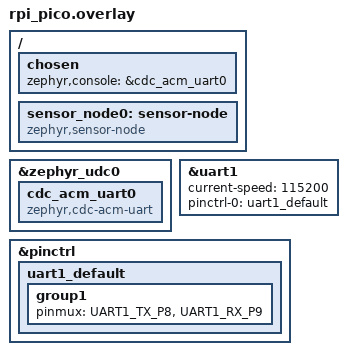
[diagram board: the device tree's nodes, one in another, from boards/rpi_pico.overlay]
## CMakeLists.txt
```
# SPDX-License-Identifier: Apache-2.0

cmake_minimum_required(VERSION 3.20.0)

find_package(Zephyr REQUIRED HINTS $ENV{ZEPHYR_BASE})
project(base_node)

target_sources(app PRIVATE
    src/main.c
    src/uart_handler.c
)
```

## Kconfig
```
# Base Node application Kconfig file

source "Kconfig.zephyr"

# Custom Kconfig options for sensor node
config SENSOR_NODE_UART_DEVICE
	string "UART Device for sensor node communication"
	default "UART_0"
	help
	  UART device to use for communication with the sensor node.

config CONSOLE_UART_DEVICE
	string "UART Device for console output"
	default "UART_1"
	help
	  UART device to use for console output.

config INTERRUPT_PIN
	int "Interrupt pin number"
	default 2
	help
	  GPIO pin number used for interrupt signal from sensor node.
```

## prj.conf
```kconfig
# USB CDC ACM Configuration
CONFIG_USB_DEVICE_STACK=y
CONFIG_USB_CDC_ACM=y

# UART Configuration
CONFIG_SERIAL=y
CONFIG_UART_INTERRUPT_DRIVEN=y
CONFIG_UART_LINE_CTRL=y
CONFIG_UART_CONSOLE=y

# Console and Logging
CONFIG_CONSOLE=y
CONFIG_STDOUT_CONSOLE=y
CONFIG_PRINTK=y
CONFIG_LOG=y
CONFIG_LOG_MODE_IMMEDIATE=y
CONFIG_LOG_DEFAULT_LEVEL=3

# GPIO Configuration
CONFIG_GPIO=y

# Memory Settings
CONFIG_HEAP_MEM_POOL_SIZE=4096
CONFIG_MAIN_STACK_SIZE=1024
CONFIG_ISR_STACK_SIZE=1024

# Build Output
CONFIG_BUILD_OUTPUT_UF2=y
```

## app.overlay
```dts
/ {
    chosen {
        zephyr,console = &cdc_acm_uart0;
    };

    /* Define our sensor node device */
    sensor_node0: sensor-node {
        compatible = "sensor-node";
        status = "okay";
    };
};

&uart0 {
    current-speed = <115200>;
    status = "okay";
};

&zephyr_udc0 {
    cdc_acm_uart0: cdc_acm_uart0 {
        compatible = "zephyr,cdc-acm-uart";
    };
};
```

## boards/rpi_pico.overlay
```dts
/*
 * Base Node Device Tree Overlay
 * Configures UART, I2C, and GPIO for the base node
 */

/ {
    chosen {
        zephyr,console = &cdc_acm_uart0;
    };

    sensor_node0: sensor-node {
        compatible = "zephyr,sensor-node";
        status = "okay";
    };
};

&zephyr_udc0 {
    cdc_acm_uart0: cdc_acm_uart0 {
        compatible = "zephyr,cdc-acm-uart";
    };
};

&uart1 {
    status = "okay";
    current-speed = <115200>;
    pinctrl-0 = <&uart1_default>;
    pinctrl-names = "default";
};

&pinctrl {
    uart1_default: uart1_default {
        group1 {
            pinmux = <UART1_TX_P8>, <UART1_RX_P9>;
        };
    };
};
```

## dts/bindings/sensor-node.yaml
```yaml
# Copyright (c) 2023
# SPDX-License-Identifier: Apache-2.0

description: Sensor Node UART-based sensor

compatible: "sensor-node"

include: base.yaml

properties:
  status:
    required: true
```

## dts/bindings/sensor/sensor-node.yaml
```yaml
description: Sensor Node Protocol

compatible: "sensor-node"

include: uart-device.yaml

properties:
  label:
    type: string
    description: Human readable string describing the device
```

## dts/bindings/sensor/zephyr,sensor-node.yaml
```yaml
description: Sensor Node Protocol Driver

compatible: "zephyr,sensor-node"

include: uart-device.yaml

properties:
  label:
    type: string
    required: true
    description: Human readable string describing the device
```

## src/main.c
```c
/**
 * @file main.c
 * @brief Main application for smart garden base node
 */
#include <zephyr/kernel.h>
#include <zephyr/device.h>
#include <zephyr/drivers/sensor.h>
#include <zephyr/logging/log.h>
#include <zephyr/usb/usb_device.h>
#include "uart_handler.h"

LOG_MODULE_REGISTER(main, CONFIG_LOG_DEFAULT_LEVEL);

/* Custom sensor channels */
enum {
    SENSOR_NODE_CHAN_SOIL_MOISTURE = SENSOR_CHAN_PRIV_START,
    SENSOR_NODE_CHAN_GAS_RESISTANCE
};

/* Thread stack size */
#define STACK_SIZE 1024

/* Thread priority */
#define PRIORITY 7

/* Stack area for the sensor thread */
K_THREAD_STACK_DEFINE(sensor_thread_stack, STACK_SIZE);
static struct k_thread sensor_thread_data;

/* Helper function to display sensor value */
static void print_sensor_value(const struct device *dev, enum sensor_channel chan, 
                              const char *name, const char *unit)
{
    struct sensor_value val;
    int ret = sensor_channel_get(dev, chan, &val);
    
    if (ret == 0) {
        LOG_INF("%s: %.2f %s", name, sensor_value_to_double(&val), unit);
    } else if (ret == -ENOTSUP) {
        LOG_INF("%s: Channel not supported", name);
    } else {
        LOG_ERR("%s: Error getting value: %d", name, ret);
    }
}

/* Sensor reading thread */
static void sensor_thread(void *p1, void *p2, void *p3)
{
    const struct device *dev = p1;
    int ret;

    while (1) {
        ret = sensor_sample_fetch(dev);  // Remove SENSOR_CHAN_ALL parameter
        if (ret < 0) {
            LOG_ERR("Error fetching sensor data: %d", ret);
        } else {
            LOG_DBG("Sensor data fetched successfully");
            print_sensor_value(dev, SENSOR_CHAN_AMBIENT_TEMP, "Temperature", "°C");
            print_sensor_value(dev, SENSOR_CHAN_HUMIDITY, "Humidity", "%");
            print_sensor_value(dev, SENSOR_CHAN_PRESS, "Pressure", "hPa");
            print_sensor_value(dev, SENSOR_CHAN_LIGHT, "Light", "lux");
            print_sensor_value(dev, SENSOR_NODE_CHAN_GAS_RESISTANCE, "Gas Resistance", "Ohm");
            LOG_INF("----------------------------");
        }
        k_sleep(K_SECONDS(5));
    }
}

void main(void)
{
    int ret;
    
    LOG_INF("=== Smart Garden Base Node ===");
    LOG_INF("USB Console enabled");
    
    /* Initialize USB */
    ret = usb_enable(NULL);
    if (ret != 0) {
        LOG_ERR("Failed to enable USB: %d", ret);
        return;
    }
    
    /* Wait for USB to initialize */
    k_sleep(K_SECONDS(1));
    
    /* Get sensor device */
    const struct device *sensor = DEVICE_DT_GET_ANY(sensor_node);
    if (!device_is_ready(sensor)) {
        LOG_ERR("Sensor device not ready");
        return;
    }
    
    LOG_INF("Sensor device ready - starting monitoring");
    
    /* Create sensor reading thread */
    k_thread_create(&sensor_thread_data, sensor_thread_stack,
                   K_THREAD_STACK_SIZEOF(sensor_thread_stack),
                   sensor_thread, (void *)sensor, NULL, NULL,
                   PRIORITY, 0, K_NO_WAIT);
    k_thread_name_set(&sensor_thread_data, "sensor_thread");
    
    // Initialize UART
    uart_init();
    
    while (1) {
        uart_process();
        k_sleep(K_MSEC(100));
    }
}
```

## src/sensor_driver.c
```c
/**
 * @file sensor_driver.c
 * @brief Zephyr driver implementation for sensor node
 */
#include <zephyr/kernel.h>
#include <zephyr/device.h>
#include <zephyr/drivers/sensor.h>
#include <zephyr/drivers/uart.h>
#include <zephyr/drivers/gpio.h>
#include <zephyr/sys/byteorder.h>
#include <zephyr/sys/util.h>
#include <zephyr/logging/log.h>
#include <string.h>

#include "sensor_driver.h"
#include "protocol.h"

LOG_MODULE_REGISTER(sensor_node, CONFIG_SENSOR_LOG_LEVEL);

// Device data structure
struct sensor_node_data {
    const struct device *uart_dev;
    const struct device *gpio_dev;
    struct gpio_callback gpio_cb;
    uint16_t light_value;
    uint16_t temperature_value;  // Fixed-point (0.1°C resolution)
    uint16_t moisture_value;
    bool data_ready;
    struct k_mutex lock;
    
    // Trigger support
    struct sensor_trigger_handler {
        sensor_trigger_handler_t handler;
        struct sensor_trigger trigger;
    } handlers[3];  // One handler per sensor type
};

// Communication buffer
static uint8_t rx_buffer[sizeof(protocol_packet_t)];
static int rx_buffer_index = 0;
static bool packet_received = false;
static protocol_packet_t rx_packet;

// Forward declarations
static void uart_rx_handler(const struct device *dev, void *user_data);
static void gpio_callback_handler(const struct device *dev, struct gpio_callback *cb, uint32_t pins);
static bool parse_packet(void);
static void process_packet(const struct device *dev);

/**
 * @brief Initialize the sensor node driver
 * 
 * @param dev Device instance
 * @return int 0 if successful, negative errno code otherwise
 */
int sensor_node_init(const struct device *dev) {
    struct sensor_node_data *data = dev->data;
    
    // Initialize mutex
    k_mutex_init(&data->lock);
    
    // Get UART device
    data->uart_dev = DEVICE_DT_GET(DT_ALIAS(sensor_uart));
    if (!device_is_ready(data->uart_dev)) {
        LOG_ERR("UART device not ready");
        return -ENODEV;
    }
    
    // Configure UART
    struct uart_config uart_cfg;
    uart_cfg.baudrate = 115200;
    uart_cfg.parity = UART_CFG_PARITY_NONE;
    uart_cfg.stop_bits = UART_CFG_STOP_BITS_1;
    uart_cfg.data_bits = UART_CFG_DATA_BITS_8;
    uart_cfg.flow_ctrl = UART_CFG_FLOW_CTRL_NONE;
    
    int ret = uart_configure(data->uart_dev, &uart_cfg);
    if (ret < 0) {
        LOG_ERR("Failed to configure UART: %d", ret);
        return ret;
    }
    
    // Set up UART callback
    uart_rx_enable(data->uart_dev, rx_buffer, sizeof(rx_buffer), 100);
    uart_callback_set(data->uart_dev, uart_rx_handler, (void *)dev);
    
    // Initialize GPIO for interrupt pin
    data->gpio_dev = DEVICE_DT_GET(DT_NODELABEL(gpio0));
    if (!device_is_ready(data->gpio_dev)) {
        LOG_ERR("GPIO device not ready");
        return -ENODEV;
    }
    
    // Configure interrupt pin
    ret = gpio_pin_configure(data->gpio_dev, CONFIG_INTERRUPT_PIN, 
                            GPIO_INPUT | GPIO_PULL_DOWN);
    if (ret < 0) {
        LOG_ERR("Failed to configure GPIO pin: %d", ret);
        return ret;
    }
    
    // Set up GPIO callback
    gpio_init_callback(&data->gpio_cb, gpio_callback_handler, BIT(CONFIG_INTERRUPT_PIN));
    gpio_add_callback(data->gpio_dev, &data->gpio_cb);
    gpio_pin_interrupt_configure(data->gpio_dev, CONFIG_INTERRUPT_PIN, 
                                GPIO_INT_EDGE_RISING);
    
    // Initialize sensor values
    data->light_value = 0;
    data->temperature_value = 0;
    data->moisture_value = 0;
    data->data_ready = false;
    
    // Send initial ping to verify communication
    protocol_packet_t tx_packet;
    tx_packet.start = PROTOCOL_START_BYTE;
    tx_packet.command = CMD_PING;
    tx_packet.data_length = 0;
    tx_packet.checksum = PROTOCOL_START_BYTE ^ CMD_PING ^ 0;
    
    uart_tx(data->uart_dev, (uint8_t *)&tx_packet, 4, SYS_FOREVER_MS);  // Start + cmd + len + checksum
    
    LOG_INF("Sensor node driver initialized");
    return 0;
}

/**
 * @brief Send a command to the sensor node
 * 
 * @param dev Device instance
 * @param cmd Command byte
 * @param data Data buffer
 * @param data_len Length of data buffer
 * @return int 0 if successful, negative errno code otherwise
 */
int sensor_node_send_command(const struct device *dev, uint8_t cmd, const uint8_t *data, uint8_t data_len) {
    struct sensor_node_data *drv_data = dev->data;
    
    protocol_packet_t tx_packet;
    tx_packet.start = PROTOCOL_START_BYTE;
    tx_packet.command = cmd;
    tx_packet.data_length = data_len;
    
    if (data && data_len > 0) {
        memcpy(tx_packet.data, data, data_len);
    }
    
    // Calculate checksum
    uint8_t checksum = tx_packet.start ^ tx_packet.command ^ tx_packet.data_length;
    for (int i = 0; i < data_len; i++) {
        checksum ^= tx_packet.data[i];
    }
    
    tx_packet.checksum = checksum;
    
    // Send packet over UART
    return uart_tx(drv_data->uart_dev, (uint8_t *)&tx_packet, data_len + 4, SYS_FOREVER_MS);
}

/**
 * @brief Sample data from all sensors
 * 
 * @param dev Device instance
 * @param chan Sensor channel to sample (or SENSOR_CHAN_ALL for all channels)
 * @return int 0 if successful, negative errno code otherwise
 */
int sensor_node_sample_fetch(const struct device *dev, enum sensor_channel chan) {
    struct sensor_node_data *data = dev->data;
    int ret;
    
    // Only fetch data if the requested channel is supported
    if (chan != SENSOR_CHAN_ALL && 
        chan != SENSOR_NODE_CHAN_LIGHT && 
        chan != SENSOR_NODE_CHAN_TEMPERATURE && 
        chan != SENSOR_NODE_CHAN_SOIL_MOISTURE) {
        return -ENOTSUP;
    }
    
    // Acquire lock to prevent concurrent access
    k_mutex_lock(&data->lock, K_FOREVER);
    
    uint8_t sensor_type;
    switch (chan) {
        case SENSOR_CHAN_ALL:
            sensor_type = SENSOR_ALL;
            break;
        case SENSOR_NODE_CHAN_LIGHT:
            sensor_type = SENSOR_LIGHT;
            break;
        case SENSOR_NODE_CHAN_TEMPERATURE:
            sensor_type = SENSOR_TEMPERATURE;
            break;
        case SENSOR_NODE_CHAN_SOIL_MOISTURE:
            sensor_type = SENSOR_SOIL_MOISTURE;
            break;
        default:
            k_mutex_unlock(&data->lock);
            return -ENOTSUP;
    }
    
    // Send command to read sensor data
    ret = sensor_node_send_command(dev, CMD_READ_SENSOR, &sensor_type, 1);
    if (ret < 0) {
        LOG_ERR("Failed to send read sensor command: %d", ret);
        k_mutex_unlock(&data->lock);
        return ret;
    }
    
    // Wait for response (with timeout)
    uint32_t start_time = k_uptime_get_32();
    while (!data->data_ready && (k_uptime_get_32() - start_time < 1000)) {
        k_sleep(K_MSEC(10));
    }
    
    if (!data->data_ready) {
        LOG_ERR("Timeout waiting for sensor data");
        k_mutex_unlock(&data->lock);
        return -ETIMEDOUT;
    }
    
    // Data was received and processed by the UART handler
    data->data_ready = false;
    k_mutex_unlock(&data->lock);
    
    return 0;
}

/**
 * @brief Get a sensor channel value
 * 
 * @param dev Device instance
 * @param chan Sensor channel
 * @param val Pointer to store the sensor value
 * @return int 0 if successful, negative errno code otherwise
 */
int sensor_node_channel_get(const struct device *dev, enum sensor_channel chan, struct sensor_value *val) {
    struct sensor_node_data *data = dev->data;
    
    k_mutex_lock(&data->lock, K_FOREVER);
    
    switch (chan) {
        case SENSOR_NODE_CHAN_LIGHT:
            val->val1 = data->light_value;
            val->val2 = 0;
            break;
            
        case SENSOR_NODE_CHAN_TEMPERATURE:
            // Convert fixed-point to sensor_value format (0.1°C resolution)
            val->val1 = data->temperature_value / 10;
            val->val2 = (data->temperature_value % 10) * 100000;
            break;
            
        case SENSOR_NODE_CHAN_SOIL_MOISTURE:
            val->val1 = data->moisture_value;
            val->val2 = 0;
            break;
            
        default:
            k_mutex_unlock(&data->lock);
            return -ENOTSUP;
    }
    
    k_mutex_unlock(&data->lock);
    return 0;
}

/**
 * @brief Set a sensor attribute
 * 
 * @param dev Device instance
 * @param chan Sensor channel
 * @param attr Sensor attribute
 * @param val Pointer to the attribute value
 * @return int 0 if successful, negative errno code otherwise
 */
int sensor_node_attr_set(const struct device *dev, enum sensor_channel chan, enum sensor_attribute attr, const struct sensor_value *val) {
    // This implementation supports setting thresholds as attributes
    if (attr != SENSOR_ATTR_UPPER_THRESH && attr != SENSOR_ATTR_LOWER_THRESH) {
        return -ENOTSUP;
    }
    
    uint8_t threshold_type = (attr == SENSOR_ATTR_UPPER_THRESH) ? 
                            THRESHOLD_TYPE_MAX : THRESHOLD_TYPE_MIN;
    
    uint16_t threshold = val->val1;
    
    // For temperature, we need to convert to our fixed-point format
    if (chan == SENSOR_NODE_CHAN_TEMPERATURE) {
        threshold = val->val1 * 10 + val->val2 / 100000;
    }
    
    switch (chan) {
        case SENSOR_NODE_CHAN_LIGHT:
            return sensor_node_set_light_threshold(dev, threshold, threshold_type);
            
        case SENSOR_NODE_CHAN_TEMPERATURE:
            return sensor_node_set_temperature_threshold(dev, threshold, threshold_type);
            
        case SENSOR_NODE_CHAN_SOIL_MOISTURE:
            return sensor_node_set_moisture_threshold(dev, threshold, threshold_type);
            
        default:
            return -ENOTSUP;
    }
    
    return 0;
}

/**
 * @brief Set a sensor trigger
 * 
 * @param dev Device instance
 * @param trig Pointer to the trigger configuration
 * @param handler Trigger handler function
 * @return int 0 if successful, negative errno code otherwise
 */
int sensor_node_trigger_set(const struct device *dev, const struct sensor_trigger *trig, sensor_trigger_handler_t handler) {
    struct sensor_node_data *data = dev->data;
    
    if (trig->type != SENSOR_TRIG_THRESHOLD) {
        return -ENOTSUP;
    }
    
    k_mutex_lock(&data->lock, K_FOREVER);
    
    switch (trig->chan) {
        case SENSOR_NODE_CHAN_LIGHT:
            data->handlers[0].trigger = *trig;
            data->handlers[0].handler = handler;
            break;
            
        case SENSOR_NODE_CHAN_TEMPERATURE:
            data->handlers[1].trigger = *trig;
            data->handlers[1].handler = handler;
            break;
            
        case SENSOR_NODE_CHAN_SOIL_MOISTURE:
            data->handlers[2].trigger = *trig;
            data->handlers[2].handler = handler;
            break;
            
        default:
            k_mutex_unlock(&data->lock);
            return -ENOTSUP;
    }
    
    k_mutex_unlock(&data->lock);
    return 0;
}

/**
 * @brief Set light threshold
 * 
 * @param dev Device instance
 * @param threshold Threshold value
 * @param threshold_type Type of threshold (min/max)
 * @return int 0 if successful, negative errno code otherwise
 */
int sensor_node_set_light_threshold(const struct device *dev, uint16_t threshold, uint8_t threshold_type) {
    config_data_t config;
    config.sensor_type = SENSOR_LIGHT;
    config.threshold = threshold;
    config.threshold_type = threshold_type;
    
    return sensor_node_send_command(dev, CMD_CONFIG_THRESHOLD, (uint8_t *)&config, sizeof(config));
}

/**
 * @brief Set temperature threshold
 * 
 * @param dev Device instance
 * @param threshold Threshold value
 * @param threshold_type Type of threshold (min/max)
 * @return int 0 if successful, negative errno code otherwise
 */
int sensor_node_set_temperature_threshold(const struct device *dev, uint16_t threshold, uint8_t threshold_type) {
    config_data_t config;
    config.sensor_type = SENSOR_TEMPERATURE;
    config.threshold = threshold;
    config.threshold_type = threshold_type;
    
    return sensor_node_send_command(dev, CMD_CONFIG_THRESHOLD, (uint8_t *)&config, sizeof(config));
}

/**
 * @brief Set moisture threshold
 * 
 * @param dev Device instance
 * @param threshold Threshold value
 * @param threshold_type Type of threshold (min/max)
 * @return int 0 if successful, negative errno code otherwise
 */
int sensor_node_set_moisture_threshold(const struct device *dev, uint16_t threshold, uint8_t threshold_type) {
    config_data_t config;
    config.sensor_type = SENSOR_SOIL_MOISTURE;
    config.threshold = threshold;
    config.threshold_type = threshold_type;
    
    return sensor_node_send_command(dev, CMD_CONFIG_THRESHOLD, (uint8_t *)&config, sizeof(config));
}

/**
 * @brief UART receive callback
 * 
 * @param dev UART device
 * @param user_data User data (device instance)
 */
static void uart_rx_handler(const struct device *dev, void *user_data) {
    const struct device *sensor_dev = (const struct device *)user_data;
    uint8_t c;
    
    while (uart_irq_update(dev) && uart_irq_is_pending(dev)) {
        if (uart_irq_rx_ready(dev)) {
            // Get received data
            if (uart_fifo_read(dev, &c, 1) == 1) {
                // Start of packet detection
                if (rx_buffer_index == 0 && c != PROTOCOL_START_BYTE) {
                    continue;
                }
                
                rx_buffer[rx_buffer_index++] = c;
                
                // Check if we have received a complete header (start byte, command, length)
                if (rx_buffer_index == 3) {
                    uint8_t data_length = rx_buffer[2];
                    
                    // Validate data length to prevent buffer overflow
                    if (data_length > PROTOCOL_MAX_DATA_LENGTH) {
                        // Invalid length, reset buffer
                        rx_buffer_index = 0;
                        continue;
                    }
                }
                
                // Check if we have received a complete packet (header + data + checksum)
                if (rx_buffer_index > 3) {
                    uint8_t data_length = rx_buffer[2];
                    if (rx_buffer_index == data_length + 4) {  // Start + command + length + data + checksum
                        // Parse packet
                        if (parse_packet()) {
                            packet_received = true;
                            process_packet(sensor_dev);
                        }
                        
                        // Reset buffer index for next packet
                        rx_buffer_index = 0;
                    }
                }
                
                // Buffer overflow protection
                if (rx_buffer_index >= sizeof(rx_buffer)) {
                    rx_buffer_index = 0;
                }
            }
        }
    }
}

/**
 * @brief Parse received data into packet structure
 * 
 * @return true if packet is valid, false otherwise
 */
static bool parse_packet(void) {
    memcpy(&rx_packet, rx_buffer, sizeof(protocol_packet_t));
    
    // Verify checksum
    uint8_t calculated_checksum = 0;
    for (int i = 0; i < rx_packet.data_length + 3; i++) {
        calculated_checksum ^= rx_buffer[i];
    }
    
    if (calculated_checksum != rx_packet.checksum) {
        LOG_ERR("Checksum verification failed");
        return false;
    }
    
    return true;
}

/**
 * @brief Process a received packet
 * 
 * @param dev Device instance
 */
static void process_packet(const struct device *dev) {
    struct sensor_node_data *data = dev->data;
    
    switch (rx_packet.command) {
        case CMD_ACK:
            // Acknowledgment received, nothing to do
            LOG_DBG("ACK received");
            break;
            
        case CMD_SENSOR_DATA: {
            k_mutex_lock(&data->lock, K_FOREVER);
            
            // Process sensor data
            if (rx_packet.data_length >= sizeof(sensor_data_t)) {
                sensor_data_t *sensor_data = (sensor_data_t *)rx_packet.data;
                int num_sensors = rx_packet.data_length / sizeof(sensor_data_t);
                
                // Process each sensor data
                for (int i = 0; i < num_sensors; i++) {
                    switch (sensor_data[i].sensor_type) {
                        case SENSOR_LIGHT:
                            data->light_value = sensor_data[i].value;
                            LOG_DBG("Light value: %u", data->light_value);
                            break;
                            
                        case SENSOR_TEMPERATURE:
                            data->temperature_value = sensor_data[i].value;
                            LOG_DBG("Temperature value: %u (0.1°C)", data->temperature_value);
                            break;
                            
                        case SENSOR_SOIL_MOISTURE:
                            data->moisture_value = sensor_data[i].value;
                            LOG_DBG("Moisture value: %u", data->moisture_value);
                            break;
                            
                        default:
                            LOG_WRN("Unknown sensor type: %u", sensor_data[i].sensor_type);
                            break;
                    }
                }
                
                data->data_ready = true;
            }
            
            k_mutex_unlock(&data->lock);
            break;
        }
        
        case CMD_ERROR: {
            if (rx_packet.data_length > 0) {
                LOG_ERR("Error response received: %u", rx_packet.data[0]);
            } else {
                LOG_ERR("Unknown error response received");
            }
            break;
        }
        
        case CMD_INTERRUPT: {
            if (rx_packet.data_length >= sizeof(interrupt_data_t)) {
                interrupt_data_t *interrupt_data = (interrupt_data_t *)rx_packet.data;
                
                LOG_INF("Interrupt received: sensor=%u, value=%u, threshold=%u, type=%u",
                        interrupt_data->sensor_type, interrupt_data->value,
                        interrupt_data->threshold, interrupt_data->threshold_type);
                
                // Update sensor value
                k_mutex_lock(&data->lock, K_FOREVER);
                
                switch (interrupt_data->sensor_type) {
                    case SENSOR_LIGHT:
                        data->light_value = interrupt_data->value;
                        if (data->handlers[0].handler) {
                            data->handlers[0].handler(dev, &data->handlers[0].trigger);
                        }
                        break;
                        
                    case SENSOR_TEMPERATURE:
                        data->temperature_value = interrupt_data->value;
                        if (data->handlers[1].handler) {
                            data->handlers[1].handler(dev, &data->handlers[1].trigger);
                        }
                        break;
                        
                    case SENSOR_SOIL_MOISTURE:
                        data->moisture_value = interrupt_data->value;
                        if (data->handlers[2].handler) {
                            data->handlers[2].handler(dev, &data->handlers[2].trigger);
                        }
                        break;
                }
                
                k_mutex_unlock(&data->lock);
            }
            break;
        }
        
        default:
            LOG_WRN("Unknown command received: %u", rx_packet.command);
            break;
    }
}

/**
 * @brief GPIO interrupt callback
 * 
 * @param dev GPIO device
 * @param cb GPIO callback structure
 * @param pins GPIO pins that triggered the interrupt
 */
static void gpio_callback_handler(const struct device *dev, struct gpio_callback *cb, uint32_t pins) {
    struct sensor_node_data *data = CONTAINER_OF(cb, struct sensor_node_data, gpio_cb);
    
    // GPIO interrupt received, fetch updated sensor values
    LOG_INF("Interrupt signal received from sensor node");
    
    // The actual handling will be done when the CMD_INTERRUPT packet is received
}

// Define the driver API structure
static const struct sensor_driver_api sensor_node_api = {
    .sample_fetch = sensor_node_sample_fetch,
    .channel_get = sensor_node_channel_get,
    .attr_set = sensor_node_attr_set,
    .trigger_set = sensor_node_trigger_set
};

// Define device data
static struct sensor_node_data sensor_node_data;

// Define device initialization
DEVICE_DEFINE(sensor_node, "sensor_node", sensor_node_init, NULL,
             &sensor_node_data, NULL, POST_KERNEL,
             CONFIG_SENSOR_INIT_PRIORITY, &sensor_node_api);
```

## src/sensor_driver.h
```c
/**
 * @file sensor_driver.h
 * @brief Zephyr driver for sensor node
 */
#ifndef SENSOR_DRIVER_H
#define SENSOR_DRIVER_H

#include <zephyr/device.h>
#include <zephyr/drivers/sensor.h>
#include <zephyr/drivers/uart.h>
#include <zephyr/drivers/gpio.h>
#include "protocol.h"

// Sensor channels for our custom sensor node
enum sensor_node_channel {
    SENSOR_NODE_CHAN_LIGHT = SENSOR_CHAN_PRIV_START,
    SENSOR_NODE_CHAN_TEMPERATURE,
    SENSOR_NODE_CHAN_SOIL_MOISTURE
};

// Function prototypes
int sensor_node_init(const struct device *dev);
int sensor_node_sample_fetch(const struct device *dev, enum sensor_channel chan);
int sensor_node_channel_get(const struct device *dev, enum sensor_channel chan, struct sensor_value *val);
int sensor_node_attr_set(const struct device *dev, enum sensor_channel chan, enum sensor_attribute attr, const struct sensor_value *val);
int sensor_node_trigger_set(const struct device *dev, const struct sensor_trigger *trig, sensor_trigger_handler_t handler);
int sensor_node_send_command(const struct device *dev, uint8_t cmd, const uint8_t *data, uint8_t data_len);

// Configuration thresholds
int sensor_node_set_light_threshold(const struct device *dev, uint16_t threshold, uint8_t threshold_type);
int sensor_node_set_temperature_threshold(const struct device *dev, uint16_t threshold, uint8_t threshold_type);
int sensor_node_set_moisture_threshold(const struct device *dev, uint16_t threshold, uint8_t threshold_type);

#endif /* SENSOR_DRIVER_H */
```

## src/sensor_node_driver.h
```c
/**
 * @file sensor_node_driver.h
 * @brief Zephyr sensor driver for the sensor node
 */

#ifndef SENSOR_NODE_DRIVER_H
#define SENSOR_NODE_DRIVER_H

#include <zephyr/device.h>
#include <zephyr/drivers/sensor.h>
#include <zephyr/drivers/uart.h>
#include "protocol.h"

/**
 * @brief Get the device instance for the sensor node driver
 * 
 * @return Pointer to the sensor node device or NULL if not available
 */
const struct device *sensor_node_driver_get_device(void);

/**
 * @brief Configure the sensor node
 * 
 * @param dev Device to configure
 * @param param Parameter to configure
 * @param value Value to set
 * @return 0 if successful, negative error code otherwise
 */
int sensor_node_set_config(const struct device *dev, enum config_param param, int32_t value);

/**
 * @brief Check if an interrupt has been triggered
 * 
 * @param dev Device to check
 * @param type Interrupt type to check
 * @return true if the interrupt is active, false otherwise
 */
bool sensor_node_interrupt_is_triggered(const struct device *dev, enum interrupt_type type);

/**
 * @brief Clear an interrupt
 * 
 * @param dev Device to clear
 * @param type Interrupt type to clear
 * @return 0 if successful, negative error code otherwise
 */
int sensor_node_clear_interrupt(const struct device *dev, enum interrupt_type type);

/**
 * @brief Get the last error code from the sensor node
 * 
 * @param dev Device to check
 * @return Error code or 0 if no error
 */
uint8_t sensor_node_get_last_error(const struct device *dev);

#endif /* SENSOR_NODE_DRIVER_H */
```

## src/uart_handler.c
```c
#include "uart_handler.h"
#include <zephyr/logging/log.h>

LOG_MODULE_REGISTER(uart_handler, LOG_LEVEL_INF);

static const struct device *const uart_dev = DEVICE_DT_GET(DT_NODELABEL(uart1));
static uint8_t rx_buf[UART_BUFFER_SIZE];
static uint8_t rx_pos;

static void uart_cb(const struct device *dev, void *user_data)
{
    uint8_t c;

    if (!uart_irq_update(dev)) {
        return;
    }

    if (uart_irq_rx_ready(dev)) {
        while (uart_fifo_read(dev, &c, 1) == 1) {
            // Log each received byte for debugging
            LOG_INF("Received byte: 0x%02x (%c)", c, isprint(c) ? c : '.');
            
            if (rx_pos < UART_BUFFER_SIZE - 1) {
                rx_buf[rx_pos++] = c;
                if (c == '\n') {
                    rx_buf[rx_pos] = '\0';
                    LOG_INF("Complete message: %s", rx_buf);
                    rx_pos = 0;
                }
            } else {
                rx_pos = 0;
            }
        }
    }
}

void uart_init(void)
{
    if (!device_is_ready(uart_dev)) {
        LOG_ERR("UART device not ready");
        return;
    }

    // Configure UART
    const struct uart_config config = {
        .baudrate = 115200,
        .parity = UART_CFG_PARITY_NONE,
        .stop_bits = UART_CFG_STOP_BITS_1,
        .data_bits = UART_CFG_DATA_BITS_8,
        .flow_ctrl = UART_CFG_FLOW_CTRL_NONE
    };

    int ret = uart_configure(uart_dev, &config);
    if (ret < 0) {
        LOG_ERR("Could not configure UART: %d", ret);
        return;
    }

    uart_irq_callback_set(uart_dev, uart_cb);
    uart_irq_rx_enable(uart_dev);
    LOG_INF("UART initialized");
}

void uart_process(void)
{
    // Print heartbeat message to confirm the handler is running
    static int count = 0;
    if (++count >= 100) {
        LOG_INF("UART handler running...");
        count = 0;
    }
    k_sleep(K_MSEC(10));
}
```

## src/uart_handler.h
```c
#ifndef UART_HANDLER_H
#define UART_HANDLER_H

#include <zephyr/kernel.h>
#include <zephyr/device.h>
#include <zephyr/drivers/uart.h>

#define UART_BUFFER_SIZE 256

void uart_init(void);
void uart_process(void);

#endif /* UART_HANDLER_H */
```
